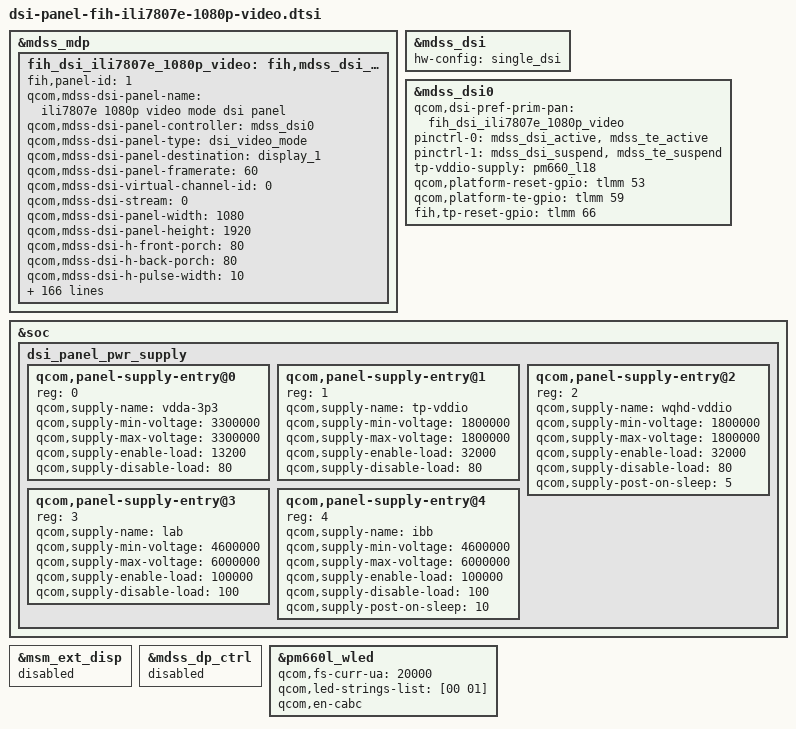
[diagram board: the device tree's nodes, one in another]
/* Copyright (c) 2013, The Linux Foundation. All rights reserved.
 *
 * This program is free software; you can redistribute it and/or modify
 * it under the terms of the GNU General Public License version 2 and
 * only version 2 as published by the Free Software Foundation.
 *
 * This program is distributed in the hope that it will be useful,
 * but WITHOUT ANY WARRANTY; without even the implied warranty of
 * MERCHANTABILITY or FITNESS FOR A PARTICULAR PURPOSE.  See the
 * GNU General Public License for more details.
 */

/*---------------------------------------------------------------------------
 * This file is autogenerated file using gcdb parser. Please do not edit it.
 * Update input XML file to add a new entry or update variable in this file
 * VERSION = "1.0"
 *---------------------------------------------------------------------------*/
&mdss_mdp {
	fih_dsi_ili7807e_1080p_video: fih,mdss_dsi_ili7807e_1080p_video {
		fih,panel-id = <1>;
		qcom,mdss-dsi-panel-name = "ili7807e 1080p video mode dsi panel";
		qcom,mdss-dsi-panel-controller = <&mdss_dsi0>;
		qcom,mdss-dsi-panel-type = "dsi_video_mode";
		qcom,mdss-dsi-panel-destination = "display_1";
		qcom,mdss-dsi-panel-framerate = <60>;
		qcom,mdss-dsi-virtual-channel-id = <0>;
		qcom,mdss-dsi-stream = <0>;
		qcom,mdss-dsi-panel-width = <1080>;
		qcom,mdss-dsi-panel-height = <1920>;
		qcom,mdss-dsi-h-front-porch = <80>;
		qcom,mdss-dsi-h-back-porch = <80>;
		qcom,mdss-dsi-h-pulse-width = <10>;
		qcom,mdss-dsi-h-sync-skew = <0>;
		qcom,mdss-dsi-v-front-porch = <8>;
		qcom,mdss-dsi-v-back-porch = <8>;
		qcom,mdss-dsi-v-pulse-width = <4>;
		qcom,mdss-dsi-h-left-border = <0>;
		qcom,mdss-dsi-h-right-border = <0>;
		qcom,mdss-dsi-v-top-border = <0>;
		qcom,mdss-dsi-v-bottom-border = <0>;
		qcom,mdss-dsi-bpp = <24>;
		qcom,mdss-dsi-color-order = "rgb_swap_rgb";
		qcom,mdss-dsi-underflow-color = <0xff>;
		qcom,mdss-dsi-border-color = <0>;
		qcom,mdss-dsi-on-command = [
			39 01 00 00 00 00 04 FF 78 07 00
			05 01 00 00 78 00 02 11 00
			05 01 00 00 0A 00 02 29 00
			/* Bist Mode
			39 01 00 00 00 00 04 FF 78 07 02
			15 01 00 00 00 00 02 2d 01
			15 01 00 00 00 00 02 2e af
			*/
			39 01 00 00 00 00 04 FF 78 07 01
			15 01 00 00 00 00 02 39 23
			15 01 00 00 00 00 02 4C 23
			15 01 00 00 00 00 02 69 23
			15 01 00 00 00 00 02 7C 23
			39 01 00 00 00 00 04 FF 78 07 00
			39 01 00 00 00 00 03 51 0F FF
			15 01 00 00 00 00 02 53 2C
			39 01 00 00 00 00 04 FF 78 07 05
			15 01 00 00 00 00 02 2D 33
			15 01 00 00 00 00 02 3C 27
			39 01 00 00 00 00 04 FF 78 07 0E
			15 01 00 00 00 00 02 53 01
			39 01 00 00 00 00 04 FF 78 07 06
			15 01 00 00 00 00 02 57 2C
			39 01 00 00 00 00 04 FF 78 07 01
			15 01 00 00 00 00 02 F3 55
			15 01 00 00 00 00 02 B2 22
			15 01 00 00 00 00 02 B5 22
			39 01 00 00 00 00 04 FF 78 07 02
			15 01 00 00 00 00 02 11 88
		];
		qcom,mdss-dsi-off-command = [
			39 01 00 00 00 00 04 FF 78 07 00
			05 01 00 00 32 00 02 28 00
			05 01 00 00 32 00 02 10 00
		];
		qcom,mdss-dsi-on-command-state = "dsi_lp_mode";
		qcom,mdss-dsi-off-command-state = "dsi_hs_mode";
		qcom,mdss-dsi-h-sync-pulse = <1>;
		qcom,mdss-dsi-traffic-mode = "burst_mode";
		qcom,mdss-dsi-lane-map = "lane_map_0123";
		qcom,mdss-dsi-bllp-eof-power-mode;
		qcom,mdss-dsi-bllp-power-mode;
		qcom,mdss-dsi-lp11-init;
              qcom,mdss-dsi-init-delay-us = <5>;
		qcom,mdss-dsi-lane-0-state;
		qcom,mdss-dsi-lane-1-state;
		qcom,mdss-dsi-lane-2-state;
		qcom,mdss-dsi-lane-3-state;
		qcom,mdss-dsi-t-clk-post = <0x15>;
		qcom,mdss-dsi-t-clk-pre = <0x32>;
		qcom,mdss-dsi-dma-trigger = "trigger_sw";
		qcom,mdss-dsi-mdp-trigger = "none";
		qcom,mdss-dsi-reset-sequence = <0 0>, <0 10>, <1 20>;

		qcom,mdss-pan-physical-width-dimension = <64>;
		qcom,mdss-pan-physical-height-dimension = <115>;
		qcom,mdss-pan-physical-width-dimension-full = <6480>;
		qcom,mdss-pan-physical-height-dimension-full = <11520>;

		/* SW4-HL-Display-ImplementCECTCABC-00+{_20160126 */
		qcom,mdss-dsi-ce-on-command = [
		];

		qcom,mdss-dsi-ce-off-command = [
		];

		qcom,mdss-dsi-ct-normal-command = [
		];

		qcom,mdss-dsi-ct-warm-command = [
		];

		qcom,mdss-dsi-ct-cold-command = [
		];

		qcom,mdss-dsi-blf-10-command = [
		];

		qcom,mdss-dsi-blf-30-command = [
		];

		qcom,mdss-dsi-blf-50-command = [
		];

		qcom,mdss-dsi-blf-75-command = [
		];

		qcom,mdss-dsi-cabc-off-command = [
			39 00 00 00 00 00 04 FF 78 07 00
			39 01 00 00 00 00 02 55 00
		];

		qcom,mdss-dsi-cabc-ui-command = [
			39 00 00 00 00 00 04 FF 78 07 00
			39 01 00 00 00 00 02 55 01
		];

		qcom,mdss-dsi-cabc-still-command = [
			39 00 00 00 00 00 04 FF 78 07 00
			39 01 00 00 00 00 02 55 02
		];

		qcom,mdss-dsi-cabc-moving-command = [
			39 00 00 00 00 00 04 FF 78 07 00
			39 01 00 00 00 00 02 55 03
			39 00 00 00 00 00 04 FF 78 07 03
			39 01 00 00 00 00 02 82 77
		];

		qcom,mdss-dsi-ce-on-command-state = "dsi_hs_mode";
		qcom,mdss-dsi-ce-off-command-state = "dsi_hs_mode";

		qcom,mdss-dsi-ct-normal-command-state = "dsi_hs_mode";
		qcom,mdss-dsi-ct-warm-command-state = "dsi_hs_mode";
		qcom,mdss-dsi-ct-cold-command-state = "dsi_hs_mode";
		qcom,mdss-dsi-blf-10-command-state = "dsi_hs_mode";
		qcom,mdss-dsi-blf-30-command-state = "dsi_hs_mode";
		qcom,mdss-dsi-blf-50-command-state = "dsi_hs_mode";
		qcom,mdss-dsi-blf-75-command-state = "dsi_hs_mode";

		qcom,mdss-dsi-cabc-off-command-state = "dsi_hs_mode";
		qcom,mdss-dsi-cabc-ui-command-state = "dsi_hs_mode";
		qcom,mdss-dsi-cabc-still-command-state = "dsi_hs_mode";
		qcom,mdss-dsi-cabc-moving-command-state = "dsi_hs_mode";
		/* SW4-HL-Display-ImplementCECTCABC-00+}

		/* SW4-HL-Display-SendCECTCABCBeforeInit-00+{_20161213 */
		qcom,mdss-dsi-ce-on-command-BeforeInit = [
		];

		qcom,mdss-dsi-ce-off-command-BeforeInit = [
		];

		qcom,mdss-dsi-ct-normal-command-BeforeInit = [
		];

		qcom,mdss-dsi-ct-warm-command-BeforeInit = [
		];

		qcom,mdss-dsi-ct-cold-command-BeforeInit = [
		];

		qcom,mdss-dsi-blf-10-command-BeforeInit = [
		];

		qcom,mdss-dsi-blf-30-command-BeforeInit = [
		];

		qcom,mdss-dsi-blf-50-command-BeforeInit = [
		];

		qcom,mdss-dsi-blf-75-command-BeforeInit = [
		];

		qcom,mdss-dsi-cabc-off-command-BeforeInit = [
			39 01 00 00 00 00 04 FF 78 07 00
			39 01 00 00 00 00 02 55 00
		];

		qcom,mdss-dsi-cabc-ui-command-BeforeInit = [
			39 01 00 00 00 00 04 FF 78 07 00
			39 01 00 00 00 00 02 55 01
		];

		qcom,mdss-dsi-cabc-still-command-BeforeInit = [
			39 01 00 00 00 00 04 FF 78 07 00
			39 01 00 00 00 00 02 55 02
		];

		qcom,mdss-dsi-cabc-moving-command-BeforeInit = [
			39 01 00 00 00 00 04 FF 78 07 00
			39 01 00 00 00 00 02 55 03
			39 01 00 00 00 00 04 FF 78 07 03
			39 01 00 00 00 00 02 82 77
		];

		qcom,mdss-dsi-ce-on-command-BeforeInit-state = "dsi_lp_mode";
		qcom,mdss-dsi-ce-off-command-BeforeInit-state = "dsi_lp_mode";

		qcom,mdss-dsi-ct-normal-command-BeforeInit-state = "dsi_lp_mode";
		qcom,mdss-dsi-ct-warm-command-BeforeInit-state = "dsi_lp_mode";
		qcom,mdss-dsi-ct-cold-command-BeforeInit-state = "dsi_lp_mode";
		qcom,mdss-dsi-blf-10-command-BeforeInit-state = "dsi_lp_mode";
		qcom,mdss-dsi-blf-30-command-BeforeInit-state = "dsi_lp_mode";
		qcom,mdss-dsi-blf-50-command-BeforeInit-state = "dsi_lp_mode";
		qcom,mdss-dsi-blf-75-command-BeforeInit-state = "dsi_lp_mode";

		qcom,mdss-dsi-cabc-off-command-BeforeInit-state = "dsi_lp_mode";
		qcom,mdss-dsi-cabc-ui-command-BeforeInit-state = "dsi_lp_mode";
		qcom,mdss-dsi-cabc-still-command-BeforeInit-state = "dsi_lp_mode";
		qcom,mdss-dsi-cabc-moving-command-BeforeInit-state = "dsi_lp_mode";
		/* SW4-HL-Display-SendCECTCABCBeforeInit-00+}

		/* SW4-HL-Display-EliminateMostDsiError-00+{_20170216 */
		qcom,mdss-dsi-tx-eot-append;
		/* SW4-HL-Display-EliminateMostDsiError-00+}_20170216 */

		/* SW4-HL-Display-DynamicReadWriteRegister-00+{_20160729 */
		fih,mdss-dsi-write-reg-command = [
			39 01 00 00 00 00 04 FF 78 07 00
		];

		fih,mdss-dsi-write-reg-command-state = "dsi_lp_mode";
		/* SW4-HL-Display-DynamicReadWriteRegister-00+}_20160729 */

		/* SW4-HL-Display-FixRedScreenWhileShutdownBacklighLed-00+{_20170614 */
		fih,bist-mode-black-pattern-command = [
			39 00 00 00 00 00 04 FF 78 07 02
			15 00 00 00 00 00 02 3E 01
			15 01 00 00 00 00 02 2D 01
		];
		fih,bist-mode-black-pattern-command-state = "dsi_hs_mode";

		fih,bist-mode-off-command = [
			39 00 00 00 00 00 04 FF 78 07 02
			15 01 00 00 00 00 02 2D 00
		];
		fih,bist-mode-off-command-state = "dsi_hs_mode";
		/* SW4-HL-Display-FixRedScreenWhileShutdownBacklighLed-00+}_20170614 */

		/* SW4-HL-Display-GlanceMode-00+{_20170524 */
		/*
		qcom,dynamic-mode-switch-enabled;
		qcom,dynamic-mode-switch-type = "dynamic-switch-immediate";
		qcom,mdss-dsi-te-pin-select= <1>;
		qcom,mdss-dsi-wr-mem-start = <0x2c>;
		qcom,mdss-dsi-wr-mem-continue = <0x3c>;
		qcom,mdss-dsi-te-dcs-command = <1>;
		qcom,mdss-dsi-te-check-enable;
		qcom,mdss-dsi-te-using-te-pin;

		qcom,adjust-timer-wakeup-ms = <1>;
		qcom,ulps-enabled;
		qcom,suspend-ulps-enabled;

		fih,aod-enabled;

		qcom,mdss-dsi-panel-on-command = [
			39 01 00 00 00 00 04 FF 78 07 00
			05 01 00 00 0A 00 02 29 00
		];
		qcom,mdss-dsi-panel-on-command-state = "dsi_lp_mode";

		qcom,mdss-dsi-aod-resume-command = [
			39 01 00 00 00 00 04 FF 78 07 00
			05 01 00 00 00 00 02 38 00
			39 01 00 00 00 00 02 34 00
		];
		qcom,mdss-dsi-aod-resume-command-state = "dsi_lp_mode";

		qcom,mdss-dsi-aod-suspend-command = [
			39 01 00 00 00 00 04 FF 78 07 06
			39 01 00 00 00 00 02 0E 48
			39 01 00 00 00 00 04 FF 78 07 00
			05 01 00 00 00 00 02 39 00
			39 01 00 00 00 00 02 35 00
		];
		qcom,mdss-dsi-aod-suspend-command-state = "dsi_lp_mode";

		fih,mdss-dsi-stop-transition-command = [
			39 01 00 00 00 00 04 FF 78 07 00
			05 01 00 00 00 00 02 59 00
		];
		fih,mdss-dsi-stop-transition-command-state = "dsi_lp_mode";

		qcom,mdss-dsi-post-mode-switch-on-command = [
			39 01 00 00 00 00 04 FF 78 07 00
			05 01 00 00 64 00 02 11 00
			05 01 00 00 0A 00 02 29 00
			39 01 00 00 00 00 04 FF 78 07 01
			15 01 00 00 00 00 02 39 23
			15 01 00 00 00 00 02 4C 23
			15 01 00 00 00 00 02 69 23
			15 01 00 00 00 00 02 7C 23
			39 01 00 00 00 00 04 FF 78 07 00
			39 01 00 00 00 00 03 51 0F FF
			15 01 00 00 00 00 02 53 2C
			39 01 00 00 00 00 04 FF 78 07 05
			15 01 00 00 00 00 02 2D 33
			15 01 00 00 00 00 02 3C 27
			39 01 00 00 00 00 04 FF 78 07 0E
			15 01 00 00 00 00 02 53 01
			39 01 00 00 00 00 04 FF 78 07 06
			15 01 00 00 00 00 02 57 2C
			39 01 00 00 00 00 04 FF 78 07 00
			39 01 00 00 14 00 02 35 00
		  ];
		  */
		/* SW4-HL-Display-GlanceMode-00+}_20170524 */

		/* SW4-HL-Display-ShowLCMAndBacklightStatus-00+{_20160304 */
		fih,mdss-dsi-switch-cmdpage-command = [
			39 01 00 00 00 00 04 FF 78 07 00
		];

		fih,mdss-dsi-switch-cmdpage-command-state = "dsi_lp_mode";
		/* SW4-HL-Display-ShowLCMAndBacklightStatus-00+}_20160304 */

		/* SW4-HL-Display-ForceLeaveGlanceModeIfPowerStatusIs0xDC-00+{_20170822 */
		fih,glance-mode-off-command = [
			39 01 00 00 00 00 04 FF 78 07 00
			05 01 00 00 00 00 02 38 00
		];
		fih,glance-mode-off-command-state = "dsi_lp_mode";
		/* SW4-HL-Display-ForceLeaveGlanceModeIfPowerStatusIs0xDC-00+}_20170822 */

		/* SW4-HL-Display-C1NO-3148-00+{_20180508 */
		/* Modify MIPI Termination Test Cmd -- START */
		fih,mipi-termination-resistor-04h-command = [
			39 01 00 00 00 00 04 FF 78 07 06
			15 01 00 00 0A 00 02 81 04
		];
		fih,mipi-termination-resistor-04h-command-state = "dsi_lp_mode";
		
		fih,mipi-termination-resistor-14h-command = [
			/*
			39 01 00 00 00 00 04 FF 78 07 06
			15 01 00 00 0A 00 02 81 14
			*/
		];
		fih,mipi-termination-resistor-14h-command-state = "dsi_lp_mode";		
		
		fih,mipi-termination-resistor-24h-command = [
			/*
			39 01 00 00 00 00 04 FF 78 07 06
			15 01 00 00 0A 00 02 81 24
			*/
		];
		fih,mipi-termination-resistor-24h-command-state = "dsi_lp_mode";	
		
		fih,mipi-termination-resistor-34h-command = [
			/*
			39 01 00 00 00 00 04 FF 78 07 06
			15 01 00 00 0A 00 02 81 34
			*/
		];
		fih,mipi-termination-resistor-34h-command-state = "dsi_lp_mode";			
		/* Modify MIPI Termination Test Cmd -- END */
		/* SW4-HL-Display-C1NO-3148-00+}_20180508 */
	};
};

&fih_dsi_ili7807e_1080p_video {
	qcom,mdss-dsi-panel-timings-phy-v2 = [
		31 2a 11 14 0d 03 04 a0
		31 2a 11 14 0d 03 04 a0
		31 2a 11 14 0d 03 04 a0
		31 2a 11 14 0d 03 04 a0
		31 3e 11 14 0d 03 04 a0
	];
	qcom,mdss-dsi-bl-pmic-control-type = "bl_ctrl_wled";
	qcom,mdss-dsi-bl-min-level = <1>;
	qcom,mdss-dsi-bl-max-level = <4095>;
	qcom,panel-supply-entries = <&dsi_panel_pwr_supply>;
};

&mdss_dsi {
	hw-config = "single_dsi";
};

&mdss_dsi0 {
	qcom,dsi-pref-prim-pan = <&fih_dsi_ili7807e_1080p_video>;
	pinctrl-names = "mdss_default", "mdss_sleep";
	pinctrl-0 = <&mdss_dsi_active &mdss_te_active>;
	pinctrl-1 = <&mdss_dsi_suspend &mdss_te_suspend>;
	tp-vddio-supply = <&pm660_l18>;		/* SW4-HL-Display-BringUpILI7807E-00+_20170327 */
	qcom,platform-reset-gpio = <&tlmm 53 0>;
	qcom,platform-te-gpio = <&tlmm 59 0>;
	fih,tp-reset-gpio = <&tlmm 66 0>;
};

&soc {
	/delete-node/dsi_panel_pwr_supply;

	dsi_panel_pwr_supply: dsi_panel_pwr_supply {
		#address-cells = <1>;
		#size-cells = <0>;

		qcom,panel-supply-entry@0 {
			reg = <0>;
			qcom,supply-name = "vdda-3p3";
			qcom,supply-min-voltage = <3300000>;
			qcom,supply-max-voltage = <3300000>;
			qcom,supply-enable-load = <13200>;
			qcom,supply-disable-load = <80>;
		};

		qcom,panel-supply-entry@1 {
			reg = <1>;
			qcom,supply-name = "tp-vddio";
			qcom,supply-min-voltage = <1800000>;
			qcom,supply-max-voltage = <1800000>;
			qcom,supply-enable-load = <32000>;
			qcom,supply-disable-load = <80>;
		};

		qcom,panel-supply-entry@2 {
			reg = <2>;
			qcom,supply-name = "wqhd-vddio";
			qcom,supply-min-voltage = <1800000>;
			qcom,supply-max-voltage = <1800000>;
			qcom,supply-enable-load = <32000>;
			qcom,supply-disable-load = <80>;
			qcom,supply-post-on-sleep = <5>;
		};

		qcom,panel-supply-entry@3 {
			reg = <3>;
			qcom,supply-name = "lab";
			qcom,supply-min-voltage = <4600000>;
			qcom,supply-max-voltage = <6000000>;
			qcom,supply-enable-load = <100000>;
			qcom,supply-disable-load = <100>;
		};

		qcom,panel-supply-entry@4 {
			reg = <4>;
			qcom,supply-name = "ibb";
			qcom,supply-min-voltage = <4600000>;
			qcom,supply-max-voltage = <6000000>;
			qcom,supply-enable-load = <100000>;
			qcom,supply-disable-load = <100>;
			qcom,supply-post-on-sleep = <10>;
		};
	};
};

&msm_ext_disp {
	status = "disabled";
};

&mdss_dp_ctrl {
	status = "disabled";
};

&pm660l_wled {
	qcom,fs-curr-ua = <20000>;
	qcom,led-strings-list = [00 01];
	qcom,en-cabc;	/* SW4-HL-Display-ImplementCECTCABC-00+_20160126 */
};

